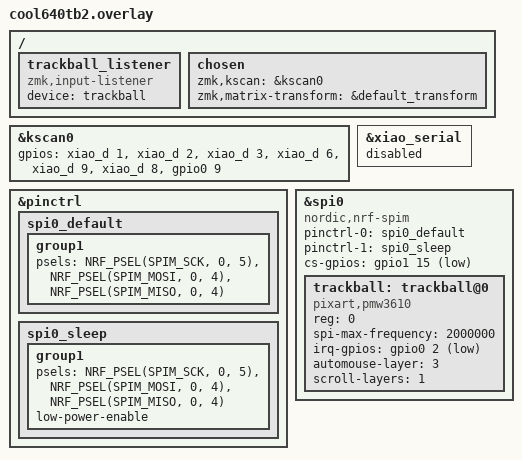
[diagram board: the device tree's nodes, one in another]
#include "cool640tb2.dtsi"

/ {
    trackball_listener {
        compatible = "zmk,input-listener";
        device = <&trackball>;

    };
};

/ {
    chosen {
        zmk,kscan = &kscan0;
        zmk,matrix-transform = &default_transform;
    };


};

&kscan0 {
        gpios
          = <&xiao_d 1 GPIO_ACTIVE_HIGH>
          , <&xiao_d 2 GPIO_ACTIVE_HIGH> 
          , <&xiao_d 3 GPIO_ACTIVE_HIGH> 
          , <&xiao_d 6 GPIO_ACTIVE_HIGH> 
          , <&xiao_d 9 GPIO_ACTIVE_HIGH> 
          , <&xiao_d 8 GPIO_ACTIVE_HIGH> 
          , <&gpio0 9 GPIO_ACTIVE_HIGH>
          ; // addressable space is 7x7, (minus paired values)
    };

&pinctrl {
    spi0_default: spi0_default {
        group1 {
            psels = <NRF_PSEL(SPIM_SCK, 0, 5)>,
                <NRF_PSEL(SPIM_MOSI, 0, 4)>,
                <NRF_PSEL(SPIM_MISO, 0, 4)>;
        };
    };

    spi0_sleep: spi0_sleep {
        group1 {
            psels = <NRF_PSEL(SPIM_SCK, 0, 5)>,
                <NRF_PSEL(SPIM_MOSI, 0, 4)>,
                <NRF_PSEL(SPIM_MISO, 0, 4)>;
            low-power-enable;
        };
    };
};

&xiao_serial { status = "disabled"; };

&spi0 {
    status = "okay";
    compatible = "nordic,nrf-spim";
    pinctrl-0 = <&spi0_default>;
    pinctrl-1 = <&spi0_sleep>;
    pinctrl-names = "default", "sleep";
    cs-gpios = <&gpio1 15 GPIO_ACTIVE_LOW>;

    trackball: trackball@0 {
        status = "okay";
        compatible = "pixart,pmw3610";
        reg = <0>;
        spi-max-frequency = <2000000>;
        irq-gpios = <&gpio0 2 (GPIO_ACTIVE_LOW | GPIO_PULL_UP)>;
        automouse-layer = <3>;
        scroll-layers = <1>;
    };
};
